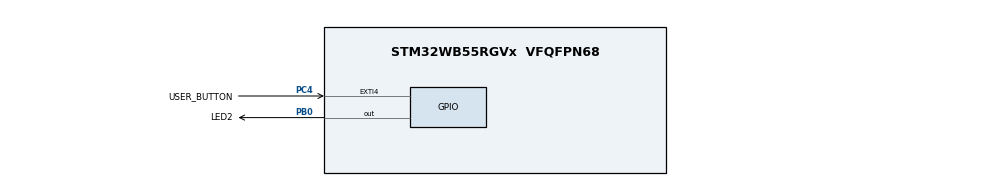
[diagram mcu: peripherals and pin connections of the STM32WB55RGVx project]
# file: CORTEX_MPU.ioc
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Mcu.Family=STM32WB
Mcu.Name=STM32WB55RGVx
Mcu.Package=VFQFPN68
NVIC.EXTI4_IRQn=true\:3\:0\:true\:false\:true\:true
NVIC.PriorityGroup=NVIC_PRIORITYGROUP_4
PB0.GPIO_Label=LED2
PB0.Signal=GPIO_Output
PC4.GPIO_Label=USER_BUTTON
PC4.GPIO_ModeDefaultEXTI=GPIO_MODE_IT_RISING_FALLING
PC4.GPIO_PuPd=GPIO_PULLUP
PC4.Signal=GPXTI4
ProjectManager.HeapSize=0x200
ProjectManager.StackSize=0x400
ProjectManager.TargetToolchain=EWARM V8
RCC.ADCFreq_Value=16000000
RCC.AHB2CLKDivider=RCC_SYSCLK_DIV2
RCC.AHBFreq_Value=16000000
RCC.APB1Freq_Value=16000000
RCC.APB1TimFreq_Value=16000000
RCC.APB2Freq_Value=16000000
RCC.APB2TimFreq_Value=16000000
RCC.APB3Freq_Value=16000000
RCC.CodegenConfigPeriph=false
RCC.CortexFreq_Value=16000000
RCC.HCLKFreq_Value=16000000
RCC.HSE_VALUE=8000000
RCC.HSI48_VALUE=48000000
RCC.HSI_VALUE=16000000
RCC.LSE_VALUE=32768
RCC.PLLN=32
RCC.SYSCLKFreq_VALUE=16000000
RCC.SYSCLKSource=RCC_SYSCLKSOURCE_HSI
RCC.USBFreq_Value=16000000
RCC.VCOOutputFreq_Value=128000000
board=custom

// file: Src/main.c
/* USER CODE BEGIN Header */
/**
  ******************************************************************************
  * @file    Examples_LL/CORTEX/CORTEX_MPU/Src/main.c
  * @author  MCD Application Team
  * @brief   This example presents the MPU features through
  *          the STM32WBxx CORTEX LL API.
  ******************************************************************************
  * @attention
  *
  * <h2><center>&copy; Copyright (c) 2019 STMicroelectronics.
  * All rights reserved.</center></h2>
  *
  * This software component is licensed by ST under BSD 3-Clause license,
  * the "License"; You may not use this file except in compliance with the
  * License. You may obtain a copy of the License at:
  *                        opensource.org/licenses/BSD-3-Clause
  *
  ******************************************************************************
  */
/* USER CODE END Header */

#include "main.h"

/* USER CODE BEGIN PD */

#define ARRAY_SIZE                               256U
#define ARRAY_ADDRESS_START                      (0x20002000UL)
#define REGION_SIZE                              LL_MPU_REGION_SIZE_256B
#define REGION_NUMBER                            LL_MPU_REGION_NUMBER3
#define EXAMPLE_RAM_ADDRESS_START                (0x20000000UL)
#define EXAMPLE_RAM_SIZE                         LL_MPU_REGION_SIZE_256KB
#define EXAMPLE_PERIPH_ADDRESS_START             (0x40000000)
#define EXAMPLE_PERIPH_SIZE                      LL_MPU_REGION_SIZE_512MB
#define EXAMPLE_FLASH_ADDRESS_START              (0x08000000)
#define EXAMPLE_FLASH_SIZE                       LL_MPU_REGION_SIZE_1MB
#define EXAMPLE_RAM_REGION_NUMBER                LL_MPU_REGION_NUMBER0
#define EXAMPLE_FLASH_REGION_NUMBER              LL_MPU_REGION_NUMBER1
#define EXAMPLE_PERIPH_REGION_NUMBER             LL_MPU_REGION_NUMBER2
#define portMPU_REGION_READ_WRITE                LL_MPU_REGION_FULL_ACCESS
#define portMPU_REGION_PRIVILEGED_READ_ONLY      LL_MPU_REGION_PRIV_RO
#define portMPU_REGION_READ_ONLY                 LL_MPU_REGION_PRIV_RO_URO
#define portMPU_REGION_PRIVILEGED_READ_WRITE     LL_MPU_REGION_PRIV_RW

/* USER CODE END PD */

/* USER CODE BEGIN PV */
#if defined ( __CC_ARM   )
uint8_t PrivilegedReadOnlyArray[ARRAY_SIZE] __attribute__((at(ARRAY_ADDRESS_START)));

#elif defined ( __ICCARM__ )
#pragma location=ARRAY_ADDRESS_START
__no_init uint8_t PrivilegedReadOnlyArray[ARRAY_SIZE];

#elif defined   (  __GNUC__  )
uint8_t PrivilegedReadOnlyArray[ARRAY_SIZE] __attribute__((section(".ROarraySection")));
#endif

__IO uint32_t accessPermitted = 0;

/* USER CODE END PV */

static void LL_Init(void);
void SystemClock_Config(void);
static void MX_GPIO_Init(void);
/* USER CODE BEGIN PFP */

void     Configure_MPU(void);
void     MPU_AccessPermConfig(void);
void     LED_Blinking(uint32_t Period);

/* USER CODE END PFP */

int main(void)
{
  /* USER CODE BEGIN 1 */

  /* Configure the system clock to 16 MHz */

  /* USER CODE END 1 */

  /* MCU Configuration--------------------------------------------------------*/

  /* Reset of all peripherals, Initializes the Flash interface and the Systick. */
  LL_Init();

  /* Configure the system clock */
  SystemClock_Config();

  /* Initialize all configured peripherals */
  MX_GPIO_Init();
  /* USER CODE BEGIN 2 */

  /* Set MPU regions */
  Configure_MPU();
  MPU_AccessPermConfig();

  /* Toggle quickly the LED in waiting for User-button press */
  LED_Blinking(LED_BLINK_FAST);

  /* USER CODE END 2 */

  /* Infinite loop */
  while (1)
  {

  }
}

static void LL_Init(void)
{

  NVIC_SetPriorityGrouping(NVIC_PRIORITYGROUP_4);

  /* System interrupt init*/
  /* MemoryManagement_IRQn interrupt configuration */
  NVIC_SetPriority(MemoryManagement_IRQn, NVIC_EncodePriority(NVIC_GetPriorityGrouping(),0, 0));
  /* BusFault_IRQn interrupt configuration */
  NVIC_SetPriority(BusFault_IRQn, NVIC_EncodePriority(NVIC_GetPriorityGrouping(),0, 0));
  /* UsageFault_IRQn interrupt configuration */
  NVIC_SetPriority(UsageFault_IRQn, NVIC_EncodePriority(NVIC_GetPriorityGrouping(),0, 0));
  /* SVCall_IRQn interrupt configuration */
  NVIC_SetPriority(SVCall_IRQn, NVIC_EncodePriority(NVIC_GetPriorityGrouping(),0, 0));
  /* DebugMonitor_IRQn interrupt configuration */
  NVIC_SetPriority(DebugMonitor_IRQn, NVIC_EncodePriority(NVIC_GetPriorityGrouping(),0, 0));
  /* PendSV_IRQn interrupt configuration */
  NVIC_SetPriority(PendSV_IRQn, NVIC_EncodePriority(NVIC_GetPriorityGrouping(),0, 0));
  /* SysTick_IRQn interrupt configuration */
  NVIC_SetPriority(SysTick_IRQn, NVIC_EncodePriority(NVIC_GetPriorityGrouping(),0, 0));

}

void SystemClock_Config(void)
{
  /* HSI configuration and activation */
  LL_RCC_HSI_Enable();
  while(LL_RCC_HSI_IsReady() != 1)
  {
  };

  /* Sysclk activation on the HSI */
  /* Set CPU1 prescaler*/
  LL_RCC_SetAHBPrescaler(LL_RCC_SYSCLK_DIV_1);

  /* Set CPU2 prescaler*/
  LL_C2_RCC_SetAHBPrescaler(LL_RCC_SYSCLK_DIV_2);

  LL_RCC_SetSysClkSource(LL_RCC_SYS_CLKSOURCE_HSI);
  while(LL_RCC_GetSysClkSource() != LL_RCC_SYS_CLKSOURCE_STATUS_HSI)
  {
  };

  /* Set AHB SHARED prescaler*/
  LL_RCC_SetAHB4Prescaler(LL_RCC_SYSCLK_DIV_1);

  /* Set APB1 prescaler*/
  LL_RCC_SetAPB1Prescaler(LL_RCC_APB1_DIV_1);

  /* Set APB2 prescaler*/
  LL_RCC_SetAPB2Prescaler(LL_RCC_APB2_DIV_1);

  LL_Init1msTick(16000000);

  /* Update CMSIS variable (which can be updated also through SystemCoreClockUpdate function) */
  LL_SetSystemCoreClock(16000000);
}

static void MX_GPIO_Init(void)
{
  LL_GPIO_InitTypeDef GPIO_InitStruct;
  LL_EXTI_InitTypeDef EXTI_InitStruct;

  /* GPIO Ports Clock Enable */
  LL_AHB2_GRP1_EnableClock(LL_AHB2_GRP1_PERIPH_GPIOC);
  LL_AHB2_GRP1_EnableClock(LL_AHB2_GRP1_PERIPH_GPIOB);

  /**/
  LL_GPIO_ResetOutputPin(LED2_GPIO_Port, LED2_Pin);

  /**/
  LL_SYSCFG_SetEXTISource(LL_SYSCFG_EXTI_PORTC, LL_SYSCFG_EXTI_LINE4);

  /**/
  EXTI_InitStruct.Line_0_31 = LL_EXTI_LINE_4;
  EXTI_InitStruct.Line_32_63 = LL_EXTI_LINE_NONE;
  EXTI_InitStruct.LineCommand = ENABLE;
  EXTI_InitStruct.Mode = LL_EXTI_MODE_IT;
  EXTI_InitStruct.Trigger = LL_EXTI_TRIGGER_RISING_FALLING;
  LL_EXTI_Init(&EXTI_InitStruct);

  /**/
  LL_GPIO_SetPinPull(USER_BUTTON_GPIO_Port, USER_BUTTON_Pin, LL_GPIO_PULL_UP);

  /**/
  LL_GPIO_SetPinMode(USER_BUTTON_GPIO_Port, USER_BUTTON_Pin, LL_GPIO_MODE_INPUT);

  /**/
  GPIO_InitStruct.Pin = LED2_Pin;
  GPIO_InitStruct.Mode = LL_GPIO_MODE_OUTPUT;
  GPIO_InitStruct.Speed = LL_GPIO_SPEED_FREQ_LOW;
  GPIO_InitStruct.OutputType = LL_GPIO_OUTPUT_PUSHPULL;
  GPIO_InitStruct.Pull = LL_GPIO_PULL_NO;
  LL_GPIO_Init(LED2_GPIO_Port, &GPIO_InitStruct);

  /* EXTI interrupt init*/
  NVIC_SetPriority(EXTI4_IRQn, NVIC_EncodePriority(NVIC_GetPriorityGrouping(),3, 0));
  NVIC_EnableIRQ(EXTI4_IRQn);

}

/* USER CODE BEGIN 4 */

/**
  * @brief  Configures the main MPU regions.
  * @param  None
  * @retval None
  */
void Configure_MPU(void)
{
  /* Disable MPU */
  LL_MPU_Disable();

  /* Configure RAM region as Region N°0, 256KB of size and R/W region */
  LL_MPU_ConfigRegion(EXAMPLE_RAM_REGION_NUMBER, 0x00, EXAMPLE_RAM_ADDRESS_START,
         EXAMPLE_RAM_SIZE | portMPU_REGION_READ_WRITE | LL_MPU_ACCESS_NOT_BUFFERABLE |
         LL_MPU_ACCESS_NOT_CACHEABLE | LL_MPU_ACCESS_NOT_SHAREABLE | LL_MPU_TEX_LEVEL0 |
         LL_MPU_INSTRUCTION_ACCESS_ENABLE);

  /* Configure FLASH region as REGION N°1, 1MB of size and R/W region */
  LL_MPU_ConfigRegion(EXAMPLE_FLASH_REGION_NUMBER, 0x00, EXAMPLE_FLASH_ADDRESS_START,
         EXAMPLE_FLASH_SIZE | portMPU_REGION_READ_WRITE | LL_MPU_ACCESS_NOT_BUFFERABLE |
         LL_MPU_ACCESS_NOT_CACHEABLE | LL_MPU_ACCESS_NOT_SHAREABLE | LL_MPU_TEX_LEVEL0 |
         LL_MPU_INSTRUCTION_ACCESS_ENABLE);

  /* Configure Peripheral region as REGION N°2, 512MB of size, R/W and Execute
  Never region */
  LL_MPU_ConfigRegion(EXAMPLE_PERIPH_REGION_NUMBER, 0x00, EXAMPLE_PERIPH_ADDRESS_START,
         EXAMPLE_PERIPH_SIZE | portMPU_REGION_READ_WRITE | LL_MPU_ACCESS_NOT_BUFFERABLE |
         LL_MPU_ACCESS_NOT_CACHEABLE | LL_MPU_ACCESS_NOT_SHAREABLE | LL_MPU_TEX_LEVEL0 |
         LL_MPU_INSTRUCTION_ACCESS_DISABLE);

  /* Enable MPU (any access not covered by any enabled region will cause a fault) */
  LL_MPU_Enable(LL_MPU_CTRL_PRIVILEGED_DEFAULT);
}

/**
  * @brief  This function configures the access right using Cortex-M4 MPU regions.
  * @param  None
  * @retval None
  */
void MPU_AccessPermConfig(void)
{
  /* Configure region for PrivilegedReadOnlyArray as REGION N°3, 32byte and R
     only in privileged mode */
  /* Disable MPU */
  LL_MPU_Disable();

  LL_MPU_ConfigRegion(REGION_NUMBER, 0x00, ARRAY_ADDRESS_START,
         REGION_SIZE | portMPU_REGION_PRIVILEGED_READ_ONLY | LL_MPU_ACCESS_NOT_BUFFERABLE |
         LL_MPU_ACCESS_NOT_CACHEABLE | LL_MPU_ACCESS_NOT_SHAREABLE | LL_MPU_TEX_LEVEL0 |
         LL_MPU_INSTRUCTION_ACCESS_ENABLE);

  /* Enable MPU (any access not covered by any enabled region will cause a fault) */
  LL_MPU_Enable(LL_MPU_CTRL_PRIVILEGED_DEFAULT);
  LL_HANDLER_EnableFault(LL_HANDLER_FAULT_MEM);

  /* Read from PrivilegedReadOnlyArray. This will not generate error */
  (void)PrivilegedReadOnlyArray[ARRAY_SIZE - 1];
}

/**
  * @brief  Set LED to Blinking mode for an infinite loop (toggle period based on value provided as input parameter).
  * @param  Period : Period of time (in ms) between each toggling of LED
  *   This parameter can be user defined values. Pre-defined values used in that example are :
  *     @arg LED_BLINK_FAST : Fast Blinking
  *     @arg LED_BLINK_SLOW : Slow Blinking
  *     @arg LED_BLINK_ERROR : Error specific Blinking
  * @retval None
  */
void LED_Blinking(uint32_t Period)
{
  /* Toggle IO in an infinite loop */
  while (1)
  {
    LL_GPIO_TogglePin(LED2_GPIO_Port, LED2_Pin);
    LL_mDelay(Period);
  }
}

/******************************************************************************/
/*   USER IRQ HANDLER TREATMENT                                               */
/******************************************************************************/
/**
  * @brief  Function to manage User button IRQ Handler
  * @param  None
  * @retval None
  */
void UserButton_Callback(void)
{
  /* This will generate error */
  PrivilegedReadOnlyArray[ARRAY_SIZE - 1] = 'e';
  accessPermitted = 1;
}

/**
  * @brief  Function to manage memory exception
  * @param  None
  * @retval None
  */
void MemManage_Callback(void)
{
  /* Turn on LED */
  LL_GPIO_SetOutputPin(LED2_GPIO_Port, LED2_Pin);

  /* Go to infinite loop when Memory Manage exception occurs */
  while (1)
  {
  }
}

/* USER CODE END 4 */

void Error_Handler(void)
{
}

/************************ (C) COPYRIGHT STMicroelectronics *****END OF FILE****/
